# nrf7120_enga_flpr register map
Vendor: Nordic Semiconductor; Series: nrf71; File version: 1
Registers are 32-bit, read-write, reset 0x0 unless marked. A register's access mark holds for its fields unless they carry their own. Offsets are from the block's base; [hi:lo] are bit positions; lines under a group give offsets from that group; {n}, {i} and the like mark numbered series; 'fields as' and 'values as' point back to an identical list.

## GLOBAL_AAR00_NS — Accelerated Address Resolver 0
Base 0x4004A000
Same registers: GLOBAL_AAR00_S 0x5004A000
0x00 TASKS_START wo — Start resolving addresses based on IRKs specified in the IRK data structure
  [0] TASKS_START
    1=Trigger task
0x04 TASKS_STOP wo — Stop resolving addresses
  [0] TASKS_STOP
    1=Trigger task
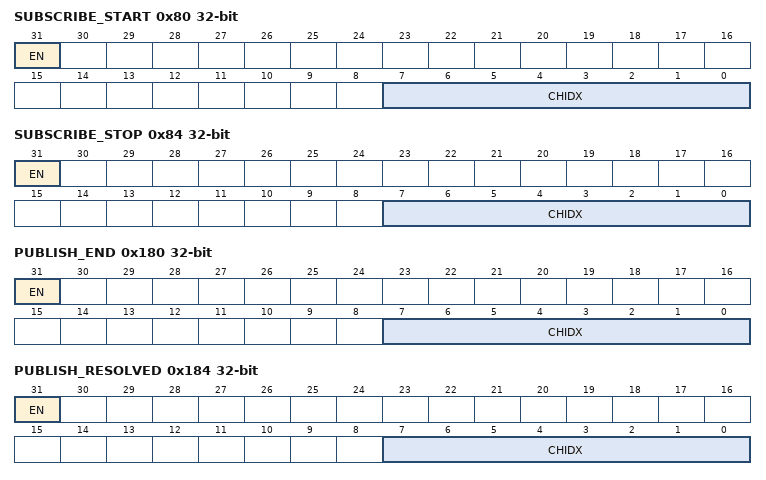
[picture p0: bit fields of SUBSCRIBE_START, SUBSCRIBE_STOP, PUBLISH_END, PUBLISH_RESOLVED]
0x80 SUBSCRIBE_START — Subscribe configuration for task START
  [31] EN
    0=Disabled (Disable subscription); 1=Enabled (Enable subscription)
  [7:0] CHIDX — DPPI channel that task START will subscribe to
0x84 SUBSCRIBE_STOP — Subscribe configuration for task STOP
  [31] EN
    values as SUBSCRIBE_START.EN
  [7:0] CHIDX — DPPI channel that task STOP will subscribe to
0x100 EVENTS_END — Address resolution procedure complete or ended due to an error
  [0] EVENTS_END
    0=NotGenerated (Event not generated); 1=Generated (Event generated)
0x104 EVENTS_RESOLVED — Address resolved
  [0] EVENTS_RESOLVED
    values as EVENTS_END.EVENTS_END
0x108 EVENTS_NOTRESOLVED — Address not resolved
  [0] EVENTS_NOTRESOLVED
    values as EVENTS_END.EVENTS_END
0x10C EVENTS_ERROR — Operation aborted because of a STOP task or due to an error
  [0] EVENTS_ERROR
    values as EVENTS_END.EVENTS_END
0x180 PUBLISH_END — Publish configuration for event END
  [31] EN
    0=Disabled (Disable publishing); 1=Enabled (Enable publishing)
  [7:0] CHIDX — DPPI channel that event END will publish to
0x184 PUBLISH_RESOLVED — Publish configuration for event RESOLVED
  [31] EN
    values as PUBLISH_END.EN
  [7:0] CHIDX — DPPI channel that event RESOLVED will publish to
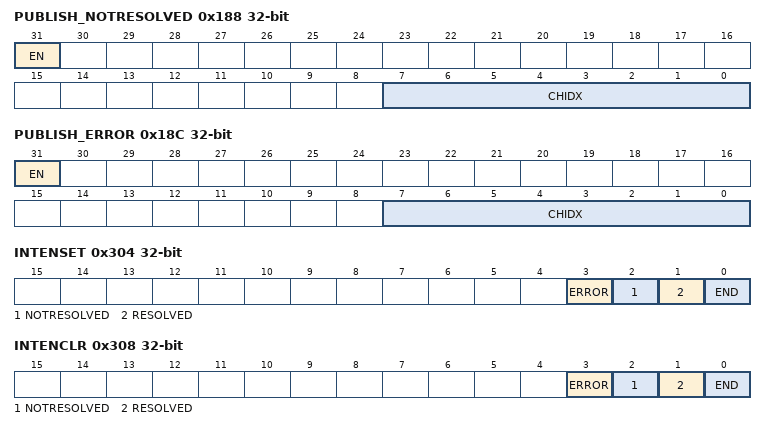
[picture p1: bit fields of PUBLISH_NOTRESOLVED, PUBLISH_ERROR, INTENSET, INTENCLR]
0x188 PUBLISH_NOTRESOLVED — Publish configuration for event NOTRESOLVED
  [31] EN
    values as PUBLISH_END.EN
  [7:0] CHIDX — DPPI channel that event NOTRESOLVED will publish to
0x18C PUBLISH_ERROR — Publish configuration for event ERROR
  [31] EN
    values as PUBLISH_END.EN
  [7:0] CHIDX — DPPI channel that event ERROR will publish to
0x304 INTENSET — Enable interrupt
  [all] fields
    on read: 0=Disabled (Read: Disabled); 1=Enabled (Read: Enabled) | on write: 1=Set (Enable)
  [3] ERROR — Write '1' to enable interrupt for event ERROR
  [2] NOTRESOLVED — Write '1' to enable interrupt for event NOTRESOLVED
  [1] RESOLVED — Write '1' to enable interrupt for event RESOLVED
  [0] END — Write '1' to enable interrupt for event END
0x308 INTENCLR — Disable interrupt
  [all] fields
    on read: 0=Disabled (Read: Disabled); 1=Enabled (Read: Enabled) | on write: 1=Clear (Disable)
  [3] ERROR — Write '1' to disable interrupt for event ERROR
  [2] NOTRESOLVED — Write '1' to disable interrupt for event NOTRESOLVED
  [1] RESOLVED — Write '1' to disable interrupt for event RESOLVED
  [0] END — Write '1' to disable interrupt for event END
0x404 ERRORSTATUS ro
  [2:0] ERRORSTATUS — Error status when the ERROR event is generated
    0=No errors have occurred; 1=PrematureInptrEnd (End of INPTR job list before data structure was read.); 2=PrematureOutptrEnd (End of OUTPTR job list before data structure was read.); 4=DmaError (Bus error during DMA access.)
0x500 ENABLE — Enable AAR
  [1:0] ENABLE — Enable or disable AAR
    0=Disabled; 3=Enabled
0x508 MAXRESOLVED reset 0x1 — Maximum number of IRKs to resolve
  [11:0] MAXRESOLVED — The maximum number of IRKs to resolve
0x530 IN group — IN EasyDMA channel
  0x00 PTR — Input pointer
    [31:0] PTR — Points to a job list containing AAR data structure
0x538 OUT group — OUT EasyDMA channel
  0x00 PTR — Output pointer
  0x04 AMOUNT ro — Number of bytes transferred in the last transaction
    [7:0] AMOUNT — Number of bytes written to memory after triggering the START task.

## GLOBAL_ECB00_NS — AES ECB Mode Encryption 0
Base 0x4004B000
Same registers: GLOBAL_ECB00_S 0x5004B000
0x00 TASKS_START wo — Start ECB block encrypt
  [0] TASKS_START
    1=Trigger task
0x04 TASKS_STOP wo — Abort a possible executing ECB operation
  [0] TASKS_STOP
    1=Trigger task
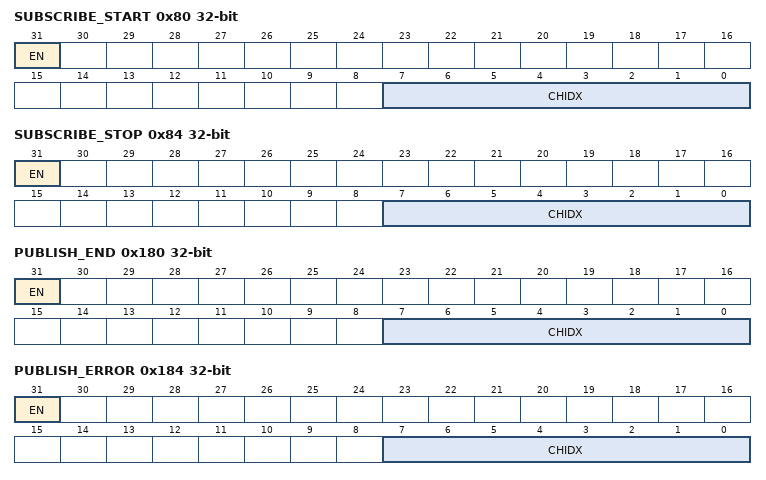
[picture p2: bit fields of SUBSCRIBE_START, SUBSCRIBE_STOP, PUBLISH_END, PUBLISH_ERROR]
0x80 SUBSCRIBE_START — Subscribe configuration for task START
  [31] EN
    0=Disabled (Disable subscription); 1=Enabled (Enable subscription)
  [7:0] CHIDX — DPPI channel that task START will subscribe to
0x84 SUBSCRIBE_STOP — Subscribe configuration for task STOP
  [31] EN
    values as SUBSCRIBE_START.EN
  [7:0] CHIDX — DPPI channel that task STOP will subscribe to
0x100 EVENTS_END — ECB block encrypt complete
  [0] EVENTS_END
    0=NotGenerated (Event not generated); 1=Generated (Event generated)
0x104 EVENTS_ERROR — ECB block encrypt aborted because of a STOP task or due to an error
  [0] EVENTS_ERROR
    values as EVENTS_END.EVENTS_END
0x180 PUBLISH_END — Publish configuration for event END
  [31] EN
    0=Disabled (Disable publishing); 1=Enabled (Enable publishing)
  [7:0] CHIDX — DPPI channel that event END will publish to
0x184 PUBLISH_ERROR — Publish configuration for event ERROR
  [31] EN
    values as PUBLISH_END.EN
  [7:0] CHIDX — DPPI channel that event ERROR will publish to
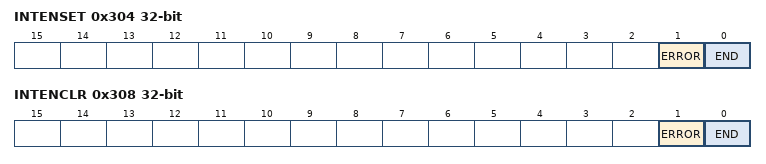
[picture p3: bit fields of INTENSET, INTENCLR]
0x304 INTENSET — Enable interrupt
  [1] ERROR — Write '1' to enable interrupt for event ERROR
    on read: 0=Disabled (Read: Disabled); 1=Enabled (Read: Enabled) | on write: 1=Set (Enable)
  [0] END — Write '1' to enable interrupt for event END
    values as ERROR
0x308 INTENCLR — Disable interrupt
  [1] ERROR — Write '1' to disable interrupt for event ERROR
    on read: 0=Disabled (Read: Disabled); 1=Enabled (Read: Enabled) | on write: 1=Clear (Disable)
  [0] END — Write '1' to disable interrupt for event END
    values as ERROR
0x400 ERRORSTATUS ro
  [2:0] ERRORSTATUS — Error status when the ERROR event is generated
    0=No errors have occurred; 1=PrematureInptrEnd (End of INPTR job list before data structure was read.); 2=PrematureOutptrEnd (End of OUTPTR job list before data structure was read.); 3=EncryptionTooSlow (Deprecated enumerator - Encryption aborted due to higher priority peripheral requesting or using the AES module.); 3=Aborted (Encryption aborted due to higher priority peripheral requesting or using the AES module.); 4=DmaError (Bus error during DMA access.)
0x510 KEY group — Unspecified
  {0x0+4j} VALUE[{j}] (j=0..3) wo — Description collection: 128-bit AES key
    [31:0] VALUE — AES 128-bit key value, bits (32*(n+1))-1 : (32*n)
0x530 IN group — IN EasyDMA channel
  0x00 PTR — Input pointer
    [31:0] PTR — Points to a job list containing unencrypted ECB data structure
0x538 OUT group — OUT EasyDMA channel
  0x00 PTR — Output pointer Points to a job list containing encrypted ECB data structure
    [31:0] PTR — Output pointer

## Notices in the file
Copyright (c) 2010 - 2025, Nordic Semiconductor ASA All rights reserved.
SPDX-License-Identifier: BSD-3-Clause
Redistribution and use in source and binary forms, with or without
modification, are permitted provided that the following conditions are met:
1. Redistributions of source code must retain the above copyright notice, this
list of conditions and the following disclaimer.
2. Redistributions in binary form must reproduce the above copyright
notice, this list of conditions and the following disclaimer in the
documentation and/or other materials provided with the distribution.
3. Neither the name of Nordic Semiconductor ASA nor the names of its
contributors may be used to endorse or promote products derived from this
software without specific prior written permission.
THIS SOFTWARE IS PROVIDED BY THE COPYRIGHT HOLDERS AND CONTRIBUTORS "AS IS"
AND ANY EXPRESS OR IMPLIED WARRANTIES, INCLUDING, BUT NOT LIMITED TO, THE
IMPLIED WARRANTIES OF MERCHANTABILITY, AND FITNESS FOR A PARTICULAR PURPOSE
ARE DISCLAIMED. IN NO EVENT SHALL NORDIC SEMICONDUCTOR ASA OR CONTRIBUTORS BE
LIABLE FOR ANY DIRECT, INDIRECT, INCIDENTAL, SPECIAL, EXEMPLARY, OR
CONSEQUENTIAL DAMAGES (INCLUDING, BUT NOT LIMITED TO, PROCUREMENT OF
SUBSTITUTE GOODS OR SERVICES; LOSS OF USE, DATA, OR PROFITS; OR BUSINESS
INTERRUPTION) HOWEVER CAUSED AND ON ANY THEORY OF LIABILITY, WHETHER IN
CONTRACT, STRICT LIABILITY, OR TORT (INCLUDING NEGLIGENCE OR OTHERWISE)
ARISING IN ANY WAY OUT OF THE USE OF THIS SOFTWARE, EVEN IF ADVISED OF THE
POSSIBILITY OF SUCH DAMAGE.
